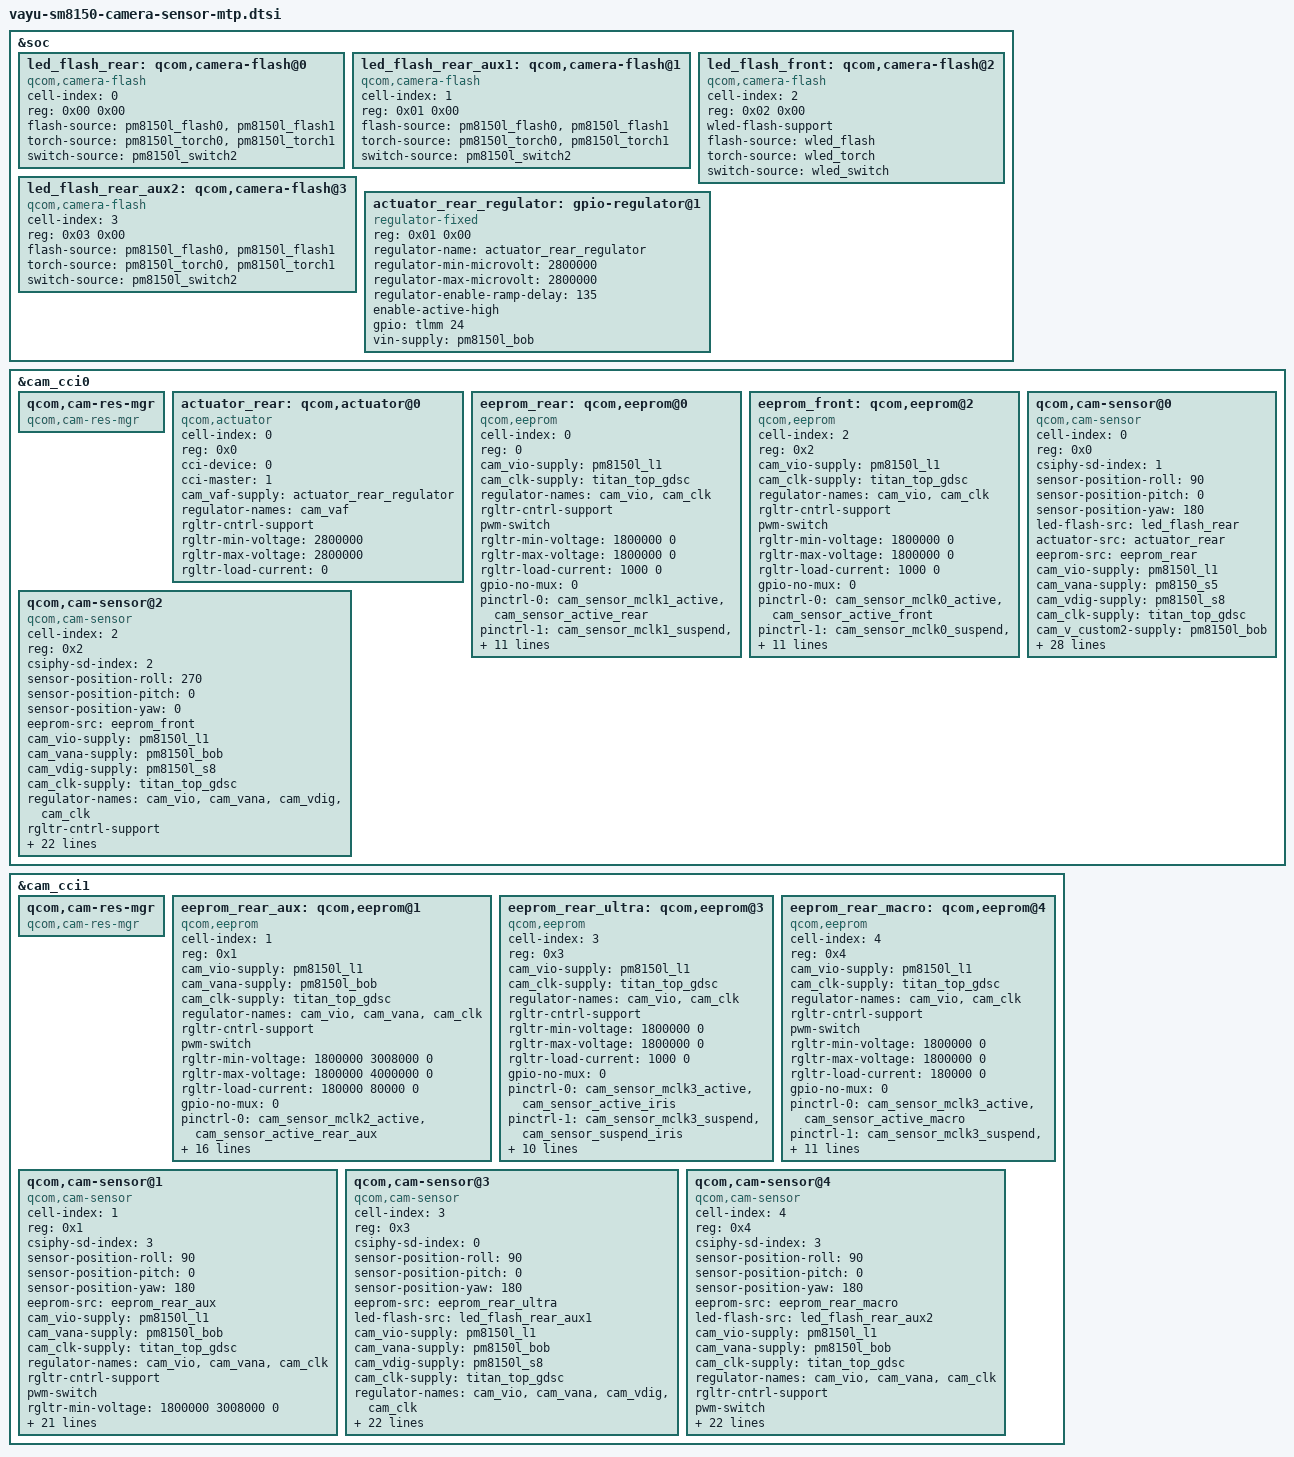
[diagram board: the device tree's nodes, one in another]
/*
 * Copyright (c) 2018, The Linux Foundation. All rights reserved.
 *
 * This program is free software; you can redistribute it and/or modify
 * it under the terms of the GNU General Public License version 2 and
 * only version 2 as published by the Free Software Foundation.
 *
 * This program is distributed in the hope that it will be useful,
 * but WITHOUT ANY WARRANTY; without even the implied warranty of
 * MERCHANTABILITY or FITNESS FOR A PARTICULAR PURPOSE.  See the
 * GNU General Public License for more details.
 */

&soc {
	led_flash_rear: qcom,camera-flash@0 {
		cell-index = <0>;
		reg = <0x00 0x00>;
		compatible = "qcom,camera-flash";
		flash-source = <&pm8150l_flash0 &pm8150l_flash1>;
		torch-source = <&pm8150l_torch0 &pm8150l_torch1>;
		switch-source = <&pm8150l_switch2>;
		status = "ok";
	};

	led_flash_rear_aux1: qcom,camera-flash@1 {
		cell-index = <1>;
		reg = <0x01 0x00>;
		compatible = "qcom,camera-flash";
		flash-source = <&pm8150l_flash0 &pm8150l_flash1>;
		torch-source = <&pm8150l_torch0 &pm8150l_torch1>;
		switch-source = <&pm8150l_switch2>;
		status = "ok";
	};

	led_flash_front: qcom,camera-flash@2 {
		cell-index = <2>;
		reg = <0x02 0x00>;
		compatible = "qcom,camera-flash";
		wled-flash-support;
		flash-source = <&wled_flash>;
		torch-source = <&wled_torch>;
		switch-source = <&wled_switch>;
		status = "ok";
	};

	led_flash_rear_aux2: qcom,camera-flash@3 {
		cell-index = <3>;
		reg = <0x03 0x00>;
		compatible = "qcom,camera-flash";
		flash-source = <&pm8150l_flash0 &pm8150l_flash1>;
		torch-source = <&pm8150l_torch0 &pm8150l_torch1>;
		switch-source = <&pm8150l_switch2>;
		status = "ok";
	};
	
	actuator_rear_regulator: gpio-regulator@1 {
		compatible = "regulator-fixed";
		reg = <0x01 0x00>;
		regulator-name = "actuator_rear_regulator";
		regulator-min-microvolt = <2800000>;
		regulator-max-microvolt = <2800000>;
		regulator-enable-ramp-delay = <135>;
		enable-active-high;
		gpio = <&tlmm 24 0>;
		vin-supply = <&pm8150l_bob>;
	};

};

&cam_cci0 {
	qcom,cam-res-mgr {
		compatible = "qcom,cam-res-mgr";
		status = "ok";
	};

	actuator_rear: qcom,actuator@0 {
		cell-index = <0>;
		reg = <0x0>;
		compatible = "qcom,actuator";
		cci-device = <0>;
		cci-master = <1>;
		cam_vaf-supply = <&actuator_rear_regulator>;
		regulator-names = "cam_vaf";
		rgltr-cntrl-support;
		rgltr-min-voltage = <2800000>;
		rgltr-max-voltage = <2800000>;
		rgltr-load-current = <0>;
	};

	eeprom_rear: qcom,eeprom@0 {
		cell-index = <0>;
		reg = <0>;
		compatible = "qcom,eeprom";
		cam_vio-supply = <&pm8150l_l1>;
		cam_clk-supply = <&titan_top_gdsc>;
                regulator-names = "cam_vio","cam_clk";
                rgltr-cntrl-support;
                pwm-switch;
                rgltr-min-voltage = <1800000 0>;
                rgltr-max-voltage = <1800000 0>;
                rgltr-load-current = <1000 0>;
                gpio-no-mux = <0>;
                pinctrl-names = "cam_default", "cam_suspend";
                pinctrl-0 = <&cam_sensor_mclk1_active
                                &cam_sensor_active_rear>;
                pinctrl-1 = <&cam_sensor_mclk1_suspend
                                &cam_sensor_suspend_rear>;
                gpios = <&tlmm 14 0>;
                gpio-req-tbl-num = <0>;
                gpio-req-tbl-flags = <1>;
                gpio-req-tbl-label = "CAMIF_MCLK0";
                sensor-mode = <0>;
                cci-device = <0>;
                cci-master = <1>;
                status = "ok";
                clocks = <&clock_camcc CAM_CC_MCLK1_CLK>;
                clock-names = "cam_clk";
                clock-cntl-level = "turbo";
                clock-rates = <19200000>;

	};

	eeprom_front: qcom,eeprom@2 {
		cell-index = <2>;
		reg = <0x2>;
		compatible = "qcom,eeprom";
                cam_vio-supply = <&pm8150l_l1>;
                cam_clk-supply = <&titan_top_gdsc>;
                regulator-names = "cam_vio","cam_clk";
                rgltr-cntrl-support;
                pwm-switch;
                rgltr-min-voltage = <1800000 0>;
                rgltr-max-voltage = <1800000 0>;
                rgltr-load-current = <1000 0>;
                gpio-no-mux = <0>;
                pinctrl-names = "cam_default", "cam_suspend";
                pinctrl-0 = <&cam_sensor_mclk0_active
                                &cam_sensor_active_front>;
                pinctrl-1 = <&cam_sensor_mclk0_suspend
                                &cam_sensor_suspend_front>;
                gpios = <&tlmm 13 0>;
                gpio-req-tbl-num = <0>;
                gpio-req-tbl-flags = <1>;
                gpio-req-tbl-label = "CAMIF_MCLK2";
                sensor-mode = <0>;
                cci-device = <0>;
                cci-master = <0>;
                status = "ok";
                clocks = <&clock_camcc CAM_CC_MCLK0_CLK>;
                clock-names = "cam_clk";
                clock-cntl-level = "turbo";
                clock-rates = <19200000>;

	};
	//imx582
	qcom,cam-sensor@0 {
		cell-index = <0>;
		compatible = "qcom,cam-sensor";
		reg = <0x0>;
		csiphy-sd-index = <1>;
		sensor-position-roll = <90>;
		sensor-position-pitch = <0>;
		sensor-position-yaw = <180>;
		led-flash-src = <&led_flash_rear>;
		actuator-src = <&actuator_rear>;
		eeprom-src = <&eeprom_rear>;
		cam_vio-supply = <&pm8150l_l1>;
		cam_vana-supply = <&pm8150_s5>;
		cam_vdig-supply = <&pm8150l_s8>;
		cam_clk-supply = <&titan_top_gdsc>;
		cam_v_custom2-supply = <&pm8150l_bob>;
		regulator-names = "cam_vio", "cam_vana", "cam_vdig", 
                      "cam_clk", "cam_v_custom2";
		rgltr-cntrl-support;
		pwm-switch;
		rgltr-min-voltage = <1800000 1904000 1352000 0 3008000>;
		rgltr-max-voltage = <1800000 2040000 1352000 0 4000000>;
		rgltr-load-current = <180000 112000 120000 0 80000>;
		gpio-no-mux = <0>;
		pinctrl-names = "cam_default", "cam_suspend";
		pinctrl-0 = <&cam_sensor_mclk1_active
				&cam_sensor_active_rear>;
		pinctrl-1 = <&cam_sensor_mclk1_suspend
				&cam_sensor_suspend_rear>;
		gpios = <&tlmm 14 0>,
			<&tlmm 30 0>,
			<&tlmm 59 0>;
		gpio-reset = <1>;
		gpio-vdig = <2>;
		gpio-req-tbl-num = <0 1 2>;
		gpio-req-tbl-flags = <1 0 0>;
		gpio-req-tbl-label = "CAMIF_MCLK0",
					"CAM_RESET0",
					"CAM_VDIG0";
		sensor-mode = <0>;
		cci-device = <0>;
		cci-master = <1>;
		status = "ok";
		clocks = <&clock_camcc CAM_CC_MCLK1_CLK>;
		clock-names = "cam_clk";
		clock-cntl-level = "turbo";
		clock-rates = <19200000>;
	};
	//s5k3t2
	qcom,cam-sensor@2 {
		cell-index = <2>;
		compatible = "qcom,cam-sensor";
		reg = <0x2>;
		csiphy-sd-index = <2>;
		sensor-position-roll = <270>;
		sensor-position-pitch = <0>;
		sensor-position-yaw = <0>;
		eeprom-src = <&eeprom_front>;
		cam_vio-supply = <&pm8150l_l1>;
		cam_vana-supply = <&pm8150l_bob>;
		cam_vdig-supply = <&pm8150l_s8>;
		cam_clk-supply = <&titan_top_gdsc>;
		regulator-names = "cam_vio", "cam_vana", "cam_vdig",
			"cam_clk";
		rgltr-cntrl-support;
		pwm-switch;
		rgltr-min-voltage = <1800000 3008000 1352000 0>;
		rgltr-max-voltage = <1800000 4000000 1352000 0>;
		rgltr-load-current = <1000 80000 120000 0>;
		gpio-no-mux = <0>;
		pinctrl-names = "cam_default", "cam_suspend";
		pinctrl-0 = <&cam_sensor_mclk0_active
				&cam_sensor_active_front>;
		pinctrl-1 = <&cam_sensor_mclk0_suspend
				&cam_sensor_suspend_front>;
		gpios = <&tlmm 13 0>,
			<&tlmm 54 0>,
			<&tlmm 118 0>;
		gpio-reset = <1>;
		gpio-vdig = <2>;
		gpio-req-tbl-num = <0 1 2>;
		gpio-req-tbl-flags = <1 0 0>;
		gpio-req-tbl-label = "CAMIF_MCLK2",
					"CAM_RESET2",
					"CAM_VDIG2";
		sensor-mode = <0>;
		cci-device = <0>;
		cci-master = <0>;
		status = "ok";
		clocks = <&clock_camcc CAM_CC_MCLK0_CLK>;
		clock-names = "cam_clk";
		clock-cntl-level = "turbo";
		clock-rates = <19200000>;
	};
};

&cam_cci1 {
	qcom,cam-res-mgr {
		compatible = "qcom,cam-res-mgr";
		status = "ok";
	};

        eeprom_rear_aux: qcom,eeprom@1 {
                cell-index = <1>;
                reg = <0x1>;
                compatible = "qcom,eeprom";
                cam_vio-supply = <&pm8150l_l1>;
                cam_vana-supply = <&pm8150l_bob>;
                cam_clk-supply = <&titan_top_gdsc>;
                regulator-names = "cam_vio", "cam_vana", "cam_clk";
                rgltr-cntrl-support;
                pwm-switch;
                rgltr-min-voltage = <1800000 3008000 0>;
                rgltr-max-voltage = <1800000 4000000 0>;
                rgltr-load-current = <180000 80000 0>;
                gpio-no-mux = <0>;
                pinctrl-names = "cam_default", "cam_suspend";
                pinctrl-0 = <&cam_sensor_mclk2_active
                                &cam_sensor_active_rear_aux>;
                pinctrl-1 = <&cam_sensor_mclk2_suspend
                                &cam_sensor_suspend_rear_aux>;
                gpios = <&tlmm 15 0>,
                        <&tlmm 23 0>,
                        <&tlmm 94 0>,
                        <&tlmm 125 0>;
                gpio-reset = <1>;
                gpio-vana = <2>;
                gpio-standby = <3>;
                gpio-req-tbl-num = <0 1 2 3>;
                gpio-req-tbl-flags = <1 0 0 0>;
                gpio-req-tbl-label = "CAMIF_MCLK1",
                                        "CAM_RESET1",
                                        "CAM_VANA1",
                                        "CAM_PWDN1";
                sensor-mode = <0>;
                cci-device = <1>;
                cci-master = <1>;
                status = "ok";
                clocks = <&clock_camcc CAM_CC_MCLK2_CLK>;
                clock-names = "cam_clk";
                clock-cntl-level = "turbo";
                clock-rates = <19200000>;

	};

        eeprom_rear_ultra: qcom,eeprom@3 {
                cell-index = <3>;
                reg = <0x3>;
                compatible = "qcom,eeprom";
                cam_vio-supply = <&pm8150l_l1>;
                cam_clk-supply = <&titan_top_gdsc>;
                regulator-names = "cam_vio", "cam_clk";
                rgltr-cntrl-support;
                rgltr-min-voltage = <1800000 0>;
                rgltr-max-voltage = <1800000 0>;
                rgltr-load-current = <1000 0>;
                gpio-no-mux = <0>;
                pinctrl-names = "cam_default", "cam_suspend";
                pinctrl-0 = <&cam_sensor_mclk3_active
                                &cam_sensor_active_iris>;
                pinctrl-1 = <&cam_sensor_mclk3_suspend
                                &cam_sensor_suspend_iris>;
                gpios = <&tlmm 16 0>;
                gpio-req-tbl-num = <0>;
                gpio-req-tbl-flags = <1>;
                gpio-req-tbl-label = "CAMIF_MCLK3";
                sensor-mode = <0>;
                cci-device = <1>;
                cci-master = <1>;
                status = "ok";
                clocks = <&clock_camcc CAM_CC_MCLK3_CLK>;
                clock-names = "cam_clk";
                clock-cntl-level = "turbo";
                clock-rates = <19200000>;
	};

        eeprom_rear_macro: qcom,eeprom@4 {
                cell-index = <4>;
                reg = <0x4>;
                compatible = "qcom,eeprom";
                cam_vio-supply = <&pm8150l_l1>;
                cam_clk-supply = <&titan_top_gdsc>;
                regulator-names = "cam_vio", "cam_clk";
                rgltr-cntrl-support;
                pwm-switch;
                rgltr-min-voltage = <1800000 0>;
                rgltr-max-voltage = <1800000 0>;
                rgltr-load-current = <180000 0>;
                gpio-no-mux = <0>;
                pinctrl-names = "cam_default", "cam_suspend";
                pinctrl-0 = <&cam_sensor_mclk3_active
                                &cam_sensor_active_macro>;
                pinctrl-1 = <&cam_sensor_mclk3_suspend
                                &cam_sensor_suspend_macro>;
                gpios = <&tlmm 16 0>;
                gpio-req-tbl-num = <0>;
                gpio-req-tbl-flags = <1>;
                gpio-req-tbl-label = "CAMIF_MCLK4";
                sensor-mode = <0>;
                cci-device = <1>;
                cci-master = <1>;
                status = "ok";
                clocks = <&clock_camcc CAM_CC_MCLK3_CLK>;
                clock-names = "cam_clk";
                clock-cntl-level = "turbo";
                clock-rates = <19200000>;
	};

	//ov02b1b
	qcom,cam-sensor@1 {
		cell-index = <1>;
		compatible = "qcom,cam-sensor";
		reg = <0x1>;
		csiphy-sd-index = <3>;
		sensor-position-roll = <90>;
		sensor-position-pitch = <0>;
		sensor-position-yaw = <180>;
		eeprom-src = <&eeprom_rear_aux>;
		cam_vio-supply = <&pm8150l_l1>;
		cam_vana-supply = <&pm8150l_bob>;
		cam_clk-supply = <&titan_top_gdsc>;
		regulator-names = "cam_vio", "cam_vana", "cam_clk";
		rgltr-cntrl-support;
		pwm-switch;
		rgltr-min-voltage = <1800000 3008000 0>;
		rgltr-max-voltage = <1800000 4000000 0>;
		rgltr-load-current = <180000 80000 0>;
		gpio-no-mux = <0>;
		pinctrl-names = "cam_default", "cam_suspend";
		pinctrl-0 = <&cam_sensor_mclk2_active
				&cam_sensor_active_rear_aux>;
		pinctrl-1 = <&cam_sensor_mclk2_suspend
				&cam_sensor_suspend_rear_aux>;
		gpios = <&tlmm 15 0>,
			<&tlmm 23 0>,
                        <&tlmm 94 0>,
			<&tlmm 125 0>;
		gpio-reset = <1>;
		gpio-vana = <2>;
		gpio-standby = <3>;
		gpio-req-tbl-num = <0 1 2 3>;
		gpio-req-tbl-flags = <1 0 0 0>;
		gpio-req-tbl-label = "CAMIF_MCLK1",
					"CAM_RESET1",
					"CAM_VANA1",
					"CAM_PWDN1";
		sensor-mode = <0>;
		cci-device = <1>;
		cci-master = <1>;
		status = "ok";
		clocks = <&clock_camcc CAM_CC_MCLK2_CLK>;
		clock-names = "cam_clk";
		clock-cntl-level = "turbo";
		clock-rates = <19200000>;
	};
	//ov8856
	qcom,cam-sensor@3 {
		cell-index = <3>;
		compatible = "qcom,cam-sensor";
		reg = <0x3>;
		csiphy-sd-index = <0>;
		sensor-position-roll = <90>;
		sensor-position-pitch = <0>;
		sensor-position-yaw = <180>;
		eeprom-src = <&eeprom_rear_ultra>;
		led-flash-src = <&led_flash_rear_aux1>;
		cam_vio-supply = <&pm8150l_l1>;
		cam_vana-supply = <&pm8150l_bob>;
		cam_vdig-supply = <&pm8150l_s8>;
		cam_clk-supply = <&titan_top_gdsc>;
		regulator-names = "cam_vio", "cam_vana", "cam_vdig", "cam_clk";
		rgltr-cntrl-support;
		rgltr-min-voltage = <1800000 3008000 1352000 0>;
		rgltr-max-voltage = <1800000 4000000 1352000 0>;
		rgltr-load-current = <1000 80000 12000 0>;
		gpio-no-mux = <0>;
		pinctrl-names = "cam_default", "cam_suspend";
		pinctrl-0 = <&cam_sensor_mclk3_active
				&cam_sensor_active_iris>;
		pinctrl-1 = <&cam_sensor_mclk3_suspend
				&cam_sensor_suspend_iris>;
		gpios = <&tlmm 16 0>,
			<&tlmm 28 0>,
			<&tlmm 94 0>;
		gpio-reset = <1>;
		gpio-vana = <2>;
		gpio-req-tbl-num = <0 1 2>;
		gpio-req-tbl-flags = <1 0 0>;
		gpio-req-tbl-label = "CAMIF_MCLK3",
					"CAM_RESET3",
					"CAM_VANA3";
		sensor-mode = <0>;
		cci-device = <1>;
		cci-master = <1>;
		status = "ok";
		clocks = <&clock_camcc CAM_CC_MCLK3_CLK>;
		clock-names = "cam_clk";
		clock-cntl-level = "turbo";
		clock-rates = <19200000>;
	};
	//hi259
	qcom,cam-sensor@4 {
		cell-index = <4>;
		compatible = "qcom,cam-sensor";
		reg = <0x4>;
		csiphy-sd-index = <3>;
		sensor-position-roll = <90>;
		sensor-position-pitch = <0>;
		sensor-position-yaw = <180>;
		eeprom-src = <&eeprom_rear_macro>;
		led-flash-src = <&led_flash_rear_aux2>;
		cam_vio-supply = <&pm8150l_l1>;
		cam_vana-supply = <&pm8150l_bob>;
		cam_clk-supply = <&titan_top_gdsc>;
		regulator-names = "cam_vio", "cam_vana", "cam_clk";
		rgltr-cntrl-support;
		pwm-switch;
		rgltr-min-voltage = <1800000 3008000 0>;
		rgltr-max-voltage = <1800000 4000000 0>;
		rgltr-load-current = <180000 112000 0>;
		gpio-no-mux = <0>;
		pinctrl-names = "cam_default", "cam_suspend";
		pinctrl-0 = <&cam_sensor_mclk3_active
				&cam_sensor_active_macro>;
		pinctrl-1 = <&cam_sensor_mclk3_suspend
				&cam_sensor_suspend_macro>;
		gpios = <&tlmm 16 0>,
			<&tlmm 27 0>,
			<&tlmm 94 0>,
			<&tlmm 84 0>;
		gpio-reset = <1>;
		gpio-vana = <2>;
		gpio-standby = <3>;
		gpio-req-tbl-num = <0 1 2 3>;
		gpio-req-tbl-flags = <1 0 0 0>;
		gpio-req-tbl-label = "CAMIF_MCLK4",
					"CAM_RESET4",
					"CAM_VANA4",
					"CAM_PWDN4";
		sensor-mode = <0>;
		cci-device = <1>;
		cci-master = <1>;
		status = "ok";
		clocks = <&clock_camcc CAM_CC_MCLK3_CLK>;
		clock-names = "cam_clk";
		clock-cntl-level = "turbo";
		clock-rates = <19200000>;
	};
};


